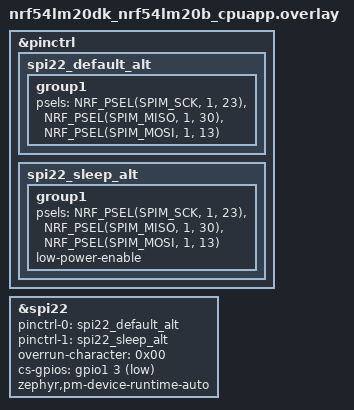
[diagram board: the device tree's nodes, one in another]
/* SPI master using spi22 — same pins as Nordic's working test */

&pinctrl {
	spi22_default_alt: spi22_default_alt {
		group1 {
			psels = <NRF_PSEL(SPIM_SCK, 1, 23)>,
				<NRF_PSEL(SPIM_MISO, 1, 30)>,
				<NRF_PSEL(SPIM_MOSI, 1, 13)>;
		};
	};

	spi22_sleep_alt: spi22_sleep_alt {
		group1 {
			psels = <NRF_PSEL(SPIM_SCK, 1, 23)>,
				<NRF_PSEL(SPIM_MISO, 1, 30)>,
				<NRF_PSEL(SPIM_MOSI, 1, 13)>;
			low-power-enable;
		};
	};
};

&spi22 {
	status = "okay";
	pinctrl-0 = <&spi22_default_alt>;
	pinctrl-1 = <&spi22_sleep_alt>;
	pinctrl-names = "default", "sleep";
	overrun-character = <0x00>;
	cs-gpios = <&gpio1 3 GPIO_ACTIVE_LOW>;
	zephyr,pm-device-runtime-auto;
};
